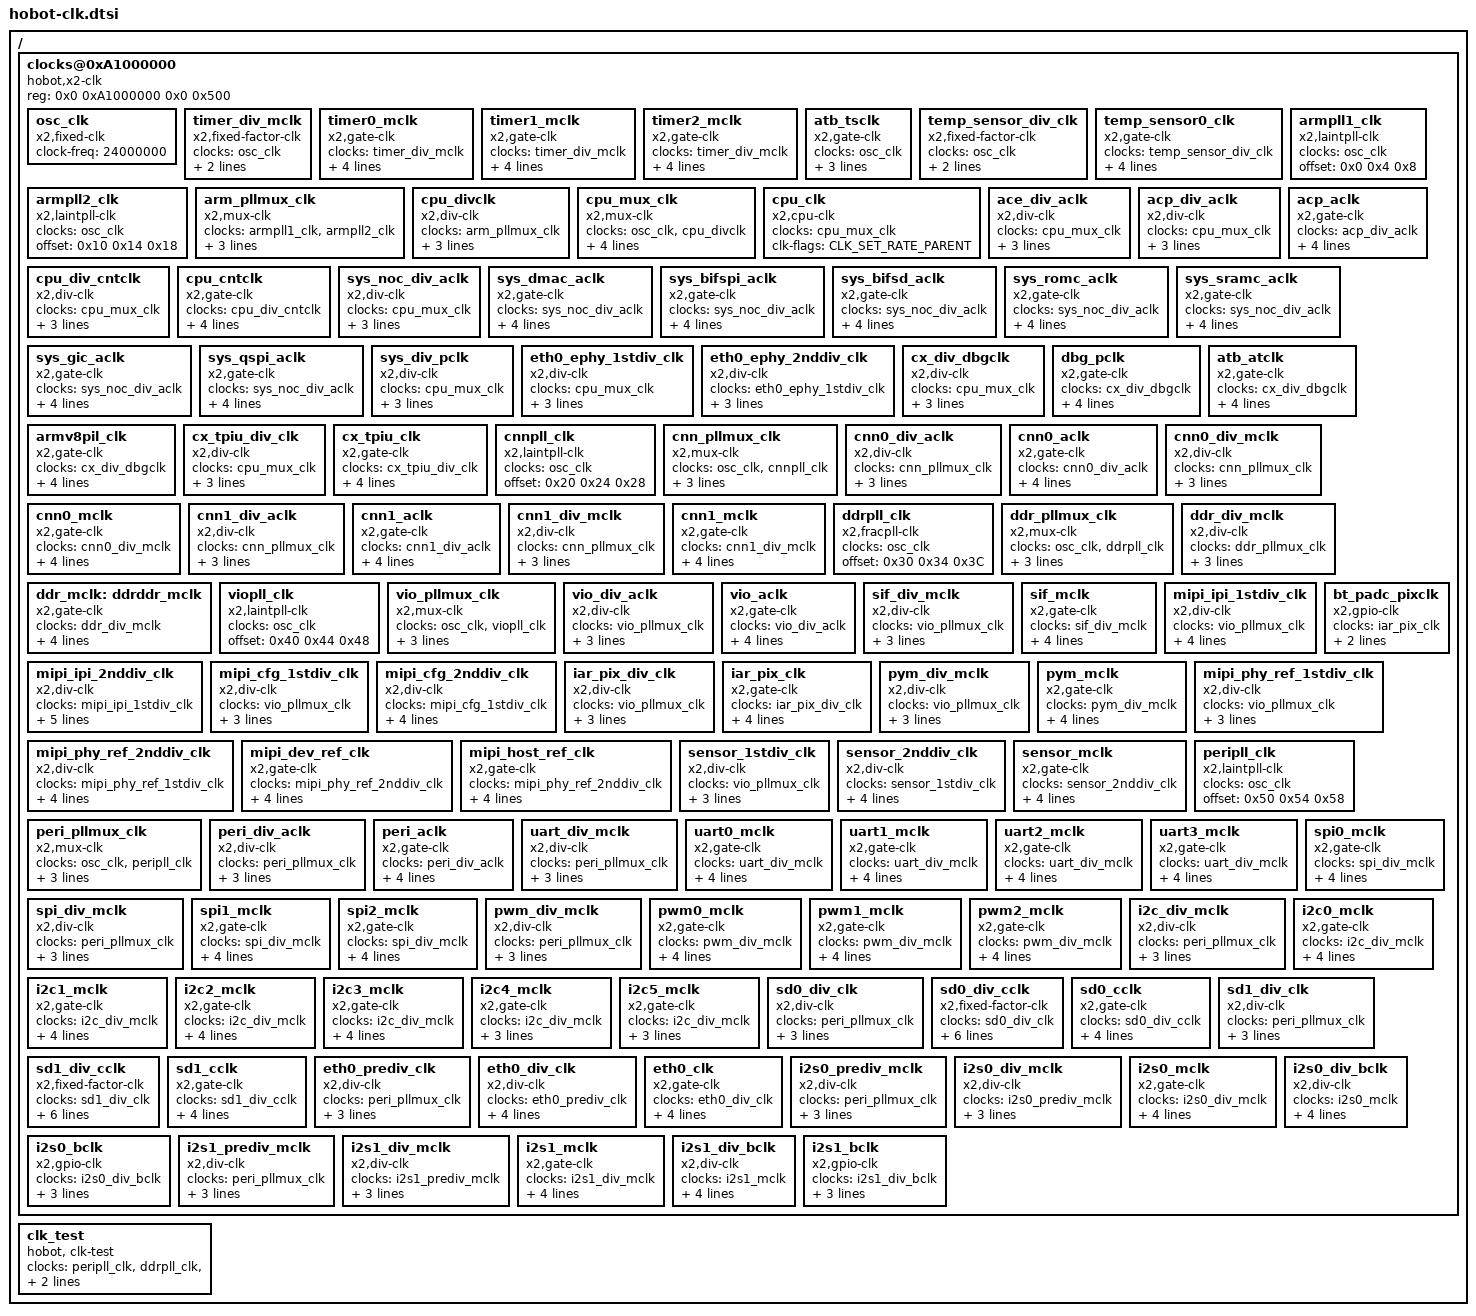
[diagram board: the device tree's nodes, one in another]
#include <dt-bindings/clk/hobot-clk.h>

/{
	clocks@0xA1000000 {
		compatible = "hobot,x2-clk";
		reg = <0x0 0xA1000000 0x0 0x500>;

		osc_clk: osc_clk {
			#clock-cells = <0>;
			compatible = "x2,fixed-clk";
			clock-freq = <24000000>;
		};

		timer_div_mclk: timer_div_mclk {
			#clock-cells = <0>;
			compatible = "x2,fixed-factor-clk";
			clocks = <&osc_clk>;
			clk-div = <24>;
			clk-mult = <1>;
		};

		timer0_mclk: timer0_mclk {
			#clock-cells = <0>;
			compatible = "x2,gate-clk";
			clocks = <&timer_div_mclk>;
			offset = <0x100 0x104 0x108 0x0>;
			bits = <8 8 8 32>;
			field = <1 1 1>;
			clk-flags = <CLK_SET_RATE_PARENT>;
		};

		timer1_mclk: timer1_mclk {
			#clock-cells = <0>;
			compatible = "x2,gate-clk";
			clocks = <&timer_div_mclk>;
			offset = <0x100 0x104 0x108 0x0>;
			bits = <9 9 9 32>;
			field = <1 1 1>;
			clk-flags = <CLK_SET_RATE_PARENT>;
		};

		timer2_mclk: timer2_mclk {
			#clock-cells = <0>;
			compatible = "x2,gate-clk";
			clocks = <&timer_div_mclk>;
			offset = <0x100 0x104 0x108 0x0>;
			bits = <10 10 10 32>;
			field = <1 1 1>;
			clk-flags = <CLK_SET_RATE_PARENT>;
		};

		atb_tsclk: atb_tsclk {
			#clock-cells = <0>;
			compatible = "x2,gate-clk";
			clocks = <&osc_clk>;
			offset = <0x110 0x114 0x118 0x0>;
			bits = <2 2 2 32>;
			field = <0x1 0x1 0x1>;
		};

		temp_sensor_div_clk: temp_sensor_div_clk {
			#clock-cells = <0>;
			compatible = "x2,fixed-factor-clk";
			clocks = <&osc_clk>;
			clk-div = <12>;
			clk-mult = <1>;
		};

		temp_sensor0_clk: temp_sensor0_clk {
			#clock-cells = <0>;
			compatible = "x2,gate-clk";
			clocks = <&temp_sensor_div_clk>;
			offset = <0x100 0x104 0x108 0x0>;
			bits = <12 12 12 32>;
			field = <1 1 1>;
			clk-flags = <CLK_SET_RATE_PARENT>;
		};

		armpll1_clk: armpll1_clk {
			#clock-cells = <0>;
			compatible = "x2,laintpll-clk";
			clocks = <&osc_clk>;
			offset = <0x0 0x4 0x8>;
		};

		armpll2_clk: armpll2_clk {
			#clock-cells = <0>;
			compatible = "x2,laintpll-clk";
			clocks = <&osc_clk>;
			offset = <0x10 0x14 0x18>;
		};

		arm_pllmux_clk: arm_pllmux_clk {
			#clock-cells = <0>;
			compatible = "x2,mux-clk";
			clocks = <&armpll1_clk>, <&armpll2_clk>;
			offset = <0x300>;
			bits = <0>;
			field = <0x1>;
		};

		cpu_divclk: cpu_divclk {
			#clock-cells = <0>;
			compatible = "x2,div-clk";
			clocks = <&arm_pllmux_clk>;
			offset = <0x204>;
			bits = <0>;
			field = <3>;
		};

		cpu_mux_clk: cpu_mux_clk {
			#clock-cells = <0>;
			compatible = "x2,mux-clk";
			clocks = <&osc_clk>, <&cpu_divclk>;
			offset = <0x300>;
			bits = <4>;
			field = <0x1>;
			clk-flags = <CLK_SET_RATE_PARENT>;
		};


		cpu_clk: cpu_clk {
			#clock-cells = <0>;
			compatible = "x2,cpu-clk";
			clocks = <&cpu_mux_clk>;
			clk-flags = <CLK_SET_RATE_PARENT>;
		};

		ace_div_aclk: ace_div_aclk {
			#clock-cells = <0>;
			compatible = "x2,div-clk";
			clocks = <&cpu_mux_clk>;
			offset = <0x204>;
			bits = <4>;
			field = <3>;
		};

		acp_div_aclk: acp_div_aclk {
			#clock-cells = <0>;
			compatible = "x2,div-clk";
			clocks = <&cpu_mux_clk>;
			offset = <0x200>;
			bits = <0>;
			field = <3>;
		};

		acp_aclk: acp_aclk {
			#clock-cells = <0>;
			compatible = "x2,gate-clk";
			clocks = <&acp_div_aclk>;
			offset = <0x100 0x104 0x108 0x208>;
			bits = <0 0 0 0>;
			field = <1 1 1 1>;
			clk-flags = <CLK_SET_RATE_PARENT>;
		};

		cpu_div_cntclk: cpu_div_cntclk {
			#clock-cells = <0>;
			compatible = "x2,div-clk";
			clocks = <&cpu_mux_clk>;
			offset = <0x200>;
			bits = <4>;
			field = <3>;
		};

		cpu_cntclk: cpu_cntclk {
			#clock-cells = <0>;
			compatible = "x2,gate-clk";
			clocks = <&cpu_div_cntclk>;
			offset = <0x100 0x104 0x108 0x208>;
			bits = <11 11 11 1>;
			field = <1 1 1 1>;
			clk-flags = <CLK_SET_RATE_PARENT>;
		};

		sys_noc_div_aclk: sys_noc_div_aclk {
			#clock-cells = <0>;
			compatible = "x2,div-clk";
			clocks = <&cpu_mux_clk>;
			offset = <0x204>;
			bits = <8>;
			field = <3>;
		};

		sys_dmac_aclk: sys_dmac_aclk {
			#clock-cells = <0>;
			compatible = "x2,gate-clk";
			clocks = <&sys_noc_div_aclk>;
			offset = <0x100 0x104 0x108 0x0>;
			bits = <7 7 7 32>;
			field = <1 1 1>;
			clk-flags = <CLK_SET_RATE_PARENT>;
		};

		sys_bifspi_aclk: sys_bifspi_aclk {
			#clock-cells = <0>;
			compatible = "x2,gate-clk";
			clocks = <&sys_noc_div_aclk>;
			offset = <0x100 0x104 0x108 0x0>;
			bits = <4 4 4 32>;
			field = <1 1 1>;
			clk-flags = <CLK_SET_RATE_PARENT>;
		};

		sys_bifsd_aclk: sys_bifsd_aclk {
			#clock-cells = <0>;
			compatible = "x2,gate-clk";
			clocks = <&sys_noc_div_aclk>;
			offset = <0x100 0x104 0x108 0x0>;
			bits = <5 5 5 32>;
			field = <1 1 1>;
			clk-flags = <CLK_SET_RATE_PARENT>;
		};

		sys_romc_aclk: sys_romc_aclk {
			#clock-cells = <0>;
			compatible = "x2,gate-clk";
			clocks = <&sys_noc_div_aclk>;
			offset = <0x100 0x104 0x108 0x0>;
			bits = <1 1 1 32>;
			field = <1 1 1>;
			clk-flags = <CLK_SET_RATE_PARENT>;
		};

		sys_sramc_aclk: sys_sramc_aclk {
			#clock-cells = <0>;
			compatible = "x2,gate-clk";
			clocks = <&sys_noc_div_aclk>;
			offset = <0x100 0x104 0x108 0x0>;
			bits = <2 2 2 32>;
			field = <1 1 1>;
			clk-flags = <CLK_SET_RATE_PARENT>;
		};

		sys_gic_aclk: sys_gic_aclk {
			#clock-cells = <0>;
			compatible = "x2,gate-clk";
			clocks = <&sys_noc_div_aclk>;
			offset = <0x100 0x104 0x108 0x0>;
			bits = <3 3 3 32>;
			field = <1 1 1>;
			clk-flags = <CLK_SET_RATE_PARENT>;
		};

		sys_qspi_aclk: sys_qspi_aclk {
			#clock-cells = <0>;
			compatible = "x2,gate-clk";
			clocks = <&sys_noc_div_aclk>;
			offset = <0x100 0x104 0x108 0x0>;
			bits = <6 6 6 32>;
			field = <1 1 1>;
			clk-flags = <CLK_SET_RATE_PARENT>;
		};

		sys_div_pclk: sys_div_pclk {
			#clock-cells = <0>;
			compatible = "x2,div-clk";
			clocks = <&cpu_mux_clk>;
			offset = <0x204>;
			bits = <12>;
			field = <3>;
		};

		eth0_ephy_1stdiv_clk: eth0_ephy_1stdiv_clk {
			#clock-cells = <0>;
			compatible = "x2,div-clk";
			clocks = <&cpu_mux_clk>;
			offset = <0x340>;
			bits = <12>;
			field = <5>;
		};

		eth0_ephy_2nddiv_clk: eth0_ephy_2nddiv_clk {
			#clock-cells = <0>;
			compatible = "x2,div-clk";
			clocks = <&eth0_ephy_1stdiv_clk>;
			offset = <0x340>;
			bits = <20>;
			field = <3>;
		};

		cx_div_dbgclk: cx_div_dbgclk {
			#clock-cells = <0>;
			compatible = "x2,div-clk";
			clocks = <&cpu_mux_clk>;
			offset = <0x210>;
			bits = <0>;
			field = <3>;
		};

		dbg_pclk: dbg_pclk {
			#clock-cells = <0>;
			compatible = "x2,gate-clk";
			clocks = <&cx_div_dbgclk>;
			offset = <0x110 0x114 0x118 0x0>;
			bits = <0 0 0 32>;
			field = <1 1 1>;
			clk-flags = <CLK_SET_RATE_PARENT>;
		};

		atb_atclk: atb_atclk {
			#clock-cells = <0>;
			compatible = "x2,gate-clk";
			clocks = <&cx_div_dbgclk>;
			offset = <0x110 0x114 0x118 0x0>;
			bits = <1 1 1 32>;
			field = <1 1 1>;
			clk-flags = <CLK_SET_RATE_PARENT>;
		};

		armv8pil_clk: armv8pil_clk {
			#clock-cells = <0>;
			compatible = "x2,gate-clk";
			clocks = <&cx_div_dbgclk>;
			offset = <0x110 0x114 0x118 0x0>;
			bits = <3 3 3 32>;
			field = <1 1 1>;
			clk-flags = <CLK_SET_RATE_PARENT>;
		};

		cx_tpiu_div_clk: cx_tpiu_div_clk {
			#clock-cells = <0>;
			compatible = "x2,div-clk";
			clocks = <&cpu_mux_clk>;
			offset = <0x210>;
			bits = <4>;
			field = <3>;
		};

		cx_tpiu_clk: cx_tpiu_clk {
			#clock-cells = <0>;
			compatible = "x2,gate-clk";
			clocks = <&cx_tpiu_div_clk>;
			offset = <0x110 0x114 0x118 0x218>;
			bits = <4 4 4 0>;
			field = <1 1 1 1>;
			clk-flags = <CLK_SET_RATE_PARENT>;
		};

		cnnpll_clk: cnnpll_clk {
			#clock-cells = <0>;
			compatible = "x2,laintpll-clk";
			clocks = <&osc_clk>;
			offset = <0x20 0x24 0x28>;
		};

		cnn_pllmux_clk: cnn_pllmux_clk {
			#clock-cells = <0>;
			compatible = "x2,mux-clk";
			clocks = <&osc_clk>, <&cnnpll_clk>;
			offset = <0x300>;
			bits = <8>;
			field = <0x1>;
		};

		cnn0_div_aclk: cnn0_div_aclk {
			#clock-cells = <0>;
			compatible = "x2,div-clk";
			clocks = <&cnn_pllmux_clk>;
			offset = <0x220>;
			bits = <0>;
			field = <3>;
		};

		cnn0_aclk: cnn0_aclk {
			#clock-cells = <0>;
			compatible = "x2,gate-clk";
			clocks = <&cnn0_div_aclk>;
			offset = <0x120 0x124 0x128 0x228>;
			bits = <0 0 0 0>;
			field = <1 1 1 1>;
			clk-flags = <CLK_SET_RATE_PARENT>;
		};

		cnn0_div_mclk: cnn0_div_mclk {
			#clock-cells = <0>;
			compatible = "x2,div-clk";
			clocks = <&cnn_pllmux_clk>;
			offset = <0x220>;
			bits = <4>;
			field = <3>;
		};

		cnn0_mclk: cnn0_mclk {
			#clock-cells = <0>;
			compatible = "x2,gate-clk";
			clocks = <&cnn0_div_mclk>;
			offset = <0x120 0x124 0x128 0x228>;
			bits = <1 1 1 1>;
			field = <1 1 1 1>;
			clk-flags = <CLK_SET_RATE_PARENT>;
		};


		cnn1_div_aclk: cnn1_div_aclk {
			#clock-cells = <0>;
			compatible = "x2,div-clk";
			clocks = <&cnn_pllmux_clk>;
			offset = <0x220>;
			bits = <8>;
			field = <3>;
		};

		cnn1_aclk: cnn1_aclk {
			#clock-cells = <0>;
			compatible = "x2,gate-clk";
			clocks = <&cnn1_div_aclk>;
			offset = <0x120 0x124 0x128 0x228>;
			bits = <4 4 4 2>;
			field = <1 1 1 1>;
			clk-flags = <CLK_SET_RATE_PARENT>;
		};

		cnn1_div_mclk: cnn1_div_mclk {
			#clock-cells = <0>;
			compatible = "x2,div-clk";
			clocks = <&cnn_pllmux_clk>;
			offset = <0x220>;
			bits = <12>;
			field = <3>;
		};

		cnn1_mclk: cnn1_mclk {
			#clock-cells = <0>;
			compatible = "x2,gate-clk";
			clocks = <&cnn1_div_mclk>;
			offset = <0x120 0x124 0x128 0x228>;
			bits = <5 5 5 3>;
			field = <1 1 1 1>;
			clk-flags = <CLK_SET_RATE_PARENT>;
		};

		ddrpll_clk: ddrpll_clk {
			#clock-cells = <0>;
			compatible = "x2,fracpll-clk";
			clocks = <&osc_clk>;
			offset = <0x30 0x34 0x3C>;
		};

		ddr_pllmux_clk: ddr_pllmux_clk {
			#clock-cells = <0>;
			compatible = "x2,mux-clk";
			clocks = <&osc_clk>, <&ddrpll_clk>;
			offset = <0x300>;
			bits = <12>;
			field = <0x1>;
		};

		ddr_div_mclk: ddr_div_mclk {
			#clock-cells = <0>;
			compatible = "x2,div-clk";
			clocks = <&ddr_pllmux_clk>;
			offset = <0x230>;
			bits = <0>;
			field = <3>;
		};

		ddr_mclk: ddrddr_mclk {
			#clock-cells = <0>;
			compatible = "x2,gate-clk";
			clocks = <&ddr_div_mclk>;
			offset = <0x130 0x134 0x138 0x238>;
			bits = <0 0 0 0>;
			field = <1 1 1 1>;
			clk-flags = <CLK_SET_RATE_PARENT>;
		};

		viopll_clk: viopll_clk {
			#clock-cells = <0>;
			compatible = "x2,laintpll-clk";
			clocks = <&osc_clk>;
			offset = <0x40 0x44 0x48>;
		};

		vio_pllmux_clk: vio_pllmux_clk {
			#clock-cells = <0>;
			compatible = "x2,mux-clk";
			clocks = <&osc_clk>, <&viopll_clk>;
			offset = <0x300>;
			bits = <16>;
			field = <0x1>;
		};

		vio_div_aclk: vio_div_aclk {
			#clock-cells = <0>;
			compatible = "x2,div-clk";
			clocks = <&vio_pllmux_clk>;
			offset = <0x240>;
			bits = <0>;
			field = <3>;
		};

		vio_aclk: vio_aclk {
			#clock-cells = <0>;
			compatible = "x2,gate-clk";
			clocks = <&vio_div_aclk>;
			offset = <0x140 0x144 0x148 0x248>;
			bits = <0 0 0 0>;
			field = <1 1 1 1>;
			clk-flags = <CLK_SET_RATE_PARENT>;
		};

		sif_div_mclk: sif_div_mclk {
			#clock-cells = <0>;
			compatible = "x2,div-clk";
			clocks = <&vio_pllmux_clk>;
			offset = <0x240>;
			bits = <12>;
			field = <3>;
		};

		sif_mclk: sif_mclk {
			#clock-cells = <0>;
			compatible = "x2,gate-clk";
			clocks = <&sif_div_mclk>;
			offset = <0x140 0x144 0x148 0x248>;
			bits = <1 1 1 1>;
			field = <1 1 1 1>;
			clk-flags = <CLK_SET_RATE_PARENT>;
		};

		mipi_ipi_1stdiv_clk: mipi_ipi_1stdiv_clk {
			#clock-cells = <0>;
			compatible = "x2,div-clk";
			clocks = <&vio_pllmux_clk>;
			offset = <0x240>;
			bits = <4>;
			field = <5>;
			clk-divider-flags = <CLK_DIVIDER_ROUND_DOWN>;
		};

		mipi_ipi_2nddiv_clk: mipi_ipi_2nddiv_clk {
			#clock-cells = <0>;
			compatible = "x2,div-clk";
			clocks = <&mipi_ipi_1stdiv_clk>;
			offset = <0x240>;
			bits = <9>;
			field = <3>;
			clk-divider-flags = <CLK_DIVIDER_ROUND_DOWN>;
			clk-flags = <CLK_SET_RATE_PARENT>;
		};

		mipi_cfg_1stdiv_clk: mipi_cfg_1stdiv_clk {
			#clock-cells = <0>;
			compatible = "x2,div-clk";
			clocks = <&vio_pllmux_clk>;
			offset = <0x240>;
			bits = <24>;
			field = <5>;
		};

		mipi_cfg_2nddiv_clk: mipi_cfg_2nddiv_clk {
			#clock-cells = <0>;
			compatible = "x2,div-clk";
			clocks = <&mipi_cfg_1stdiv_clk>;
			offset = <0x240>;
			bits = <29>;
			field = <3>;
			clk-flags = <CLK_SET_RATE_PARENT>;
		};

		iar_pix_div_clk: iar_pix_div_clk {
			#clock-cells = <0>;
			compatible = "x2,div-clk";
			clocks = <&vio_pllmux_clk>;
			offset = <0x240>;
			bits = <20>;
			field = <4>;
		};

		iar_pix_clk: iar_pix_clk {
			#clock-cells = <0>;
			compatible = "x2,gate-clk";
			clocks = <&iar_pix_div_clk>;
			offset = <0x140 0x144 0x148 0x248>;
			bits = <2 2 2 2>;
			field = <1 1 1 1>;
			clk-flags = <CLK_SET_RATE_PARENT>;
		};

		bt_padc_pixclk: bt_padc_pixclk {
			#clock-cells = <0>;
			compatible = "x2,gpio-clk";
			clocks = <&iar_pix_clk>;
			offset = <0x310>;
			bits = <16>;
		};

		pym_div_mclk: pym_div_mclk {
			#clock-cells = <0>;
			compatible = "x2,div-clk";
			clocks = <&vio_pllmux_clk>;
			offset = <0x240>;
			bits = <16>;
			field = <3>;
		};

		pym_mclk: pym_mclk {
			#clock-cells = <0>;
			compatible = "x2,gate-clk";
			clocks = <&pym_div_mclk>;
			offset = <0x140 0x144 0x148 0x248>;
			bits = <5 5 5 5>;
			field = <1 1 1 1>;
			clk-flags = <CLK_SET_RATE_PARENT>;
		};

		mipi_phy_ref_1stdiv_clk: mipi_phy_ref_1stdiv_clk {
			#clock-cells = <0>;
			compatible = "x2,div-clk";
			clocks = <&vio_pllmux_clk>;
			offset = <0x244>;
			bits = <0>;
			field = <5>;
		};

		mipi_phy_ref_2nddiv_clk: mipi_phy_ref_2nddiv_clk {
			#clock-cells = <0>;
			compatible = "x2,div-clk";
			clocks = <&mipi_phy_ref_1stdiv_clk>;
			offset = <0x244>;
			bits = <8>;
			field = <3>;
			clk-flags = <CLK_SET_RATE_PARENT>;
		};

		mipi_dev_ref_clk: mipi_dev_ref_clk {
			#clock-cells = <0>;
			compatible = "x2,gate-clk";
			clocks = <&mipi_phy_ref_2nddiv_clk>;
			offset = <0x140 0x144 0x148 0x0>;
			bits = <3 3 3 32>;
			field = <1 1 1>;
			clk-flags = <CLK_SET_RATE_PARENT>;
		};

		mipi_host_ref_clk: mipi_host_ref_clk {
			#clock-cells = <0>;
			compatible = "x2,gate-clk";
			clocks = <&mipi_phy_ref_2nddiv_clk>;
			offset = <0x140 0x144 0x148 0x0>;
			bits = <6 6 6 32>;
			field = <1 1 1>;
			clk-flags = <CLK_SET_RATE_PARENT>;
		};

		sensor_1stdiv_clk: sensor_1stdiv_clk {
			#clock-cells = <0>;
			compatible = "x2,div-clk";
			clocks = <&vio_pllmux_clk>;
			offset = <0x244>;
			bits = <12>;
			field = <5>;
		};

		sensor_2nddiv_clk: sensor_2nddiv_clk {
			#clock-cells = <0>;
			compatible = "x2,div-clk";
			clocks = <&sensor_1stdiv_clk>;
			offset = <0x244>;
			bits = <20>;
			field = <3>;
			clk-flags = <CLK_SET_RATE_PARENT>;
		};

		sensor_mclk: sensor_mclk {
			#clock-cells = <0>;
			compatible = "x2,gate-clk";
			clocks = <&sensor_2nddiv_clk>;
			offset = <0x140 0x144 0x148 0x248>;
			bits = <4 4 4 4>;
			field = <1 1 1 1>;
			clk-flags = <CLK_SET_RATE_PARENT>;
		};

		peripll_clk: peripll_clk {
			#clock-cells = <0>;
			compatible = "x2,laintpll-clk";
			clocks = <&osc_clk>;
			offset = <0x50 0x54 0x58>;
		};

		peri_pllmux_clk: peri_pllmux_clk {
			#clock-cells = <0>;
			compatible = "x2,mux-clk";
			clocks = <&osc_clk>, <&peripll_clk>;
			offset = <0x300>;
			bits = <20>;
			field = <0x1>;
		};

		peri_div_aclk: peri_div_aclk {
			#clock-cells = <0>;
			compatible = "x2,div-clk";
			clocks = <&peri_pllmux_clk>;
			offset = <0x250>;
			bits = <0>;
			field = <3>;
		};

		peri_aclk: peri_aclk {
			#clock-cells = <0>;
			compatible = "x2,gate-clk";
			clocks = <&peri_div_aclk>;
			offset = <0x150 0x154 0x158 0x258>;
			bits = <0 0 0 0>;
			field = <1 1 1 1>;
			clk-flags = <CLK_SET_RATE_PARENT>;
		};

		uart_div_mclk: uart_div_mclk {
			#clock-cells = <0>;
			compatible = "x2,div-clk";
			clocks = <&peri_pllmux_clk>;
			offset = <0x250>;
			bits = <4>;
			field = <4>;
		};

		uart0_mclk: uart0_mclk {
			#clock-cells = <0>;
			compatible = "x2,gate-clk";
			clocks = <&uart_div_mclk>;
			offset = <0x150 0x154 0x158 0x0>;
			bits = <1 1 1 32>;
			field = <0x1 0x1 0x1>;
			clk-flags = <CLK_SET_RATE_PARENT>;
		};

		uart1_mclk: uart1_mclk {
			#clock-cells = <0>;
			compatible = "x2,gate-clk";
			clocks = <&uart_div_mclk>;
			offset = <0x150 0x154 0x158 0x0>;
			bits = <2 2 2 32>;
			field = <1 1 1>;
			clk-flags = <CLK_SET_RATE_PARENT>;
		};

		uart2_mclk: uart2_mclk {
			#clock-cells = <0>;
			compatible = "x2,gate-clk";
			clocks = <&uart_div_mclk>;
			offset = <0x150 0x154 0x158 0x0>;
			bits = <3 3 3 32>;
			field = <1 1 1>;
			clk-flags = <CLK_SET_RATE_PARENT>;
		};

		uart3_mclk: uart3_mclk {
			#clock-cells = <0>;
			compatible = "x2,gate-clk";
			clocks = <&uart_div_mclk>;
			offset = <0x150 0x154 0x158 0x0>;
			bits = <4 4 4 32>;
			field = <1 1 1>;
			clk-flags = <CLK_SET_RATE_PARENT>;
		};

		spi_div_mclk: spi_div_mclk {
			#clock-cells = <0>;
			compatible = "x2,div-clk";
			clocks = <&peri_pllmux_clk>;
			offset = <0x250>;
			bits = <8>;
			field = <4>;
		};

		spi0_mclk: spi0_mclk {
			#clock-cells = <0>;
			compatible = "x2,gate-clk";
			clocks = <&spi_div_mclk>;
			offset = <0x150 0x154 0x158 0x0>;
			bits = <5 5 5 32>;
			field = <1 1 1>;
			clk-flags = <CLK_SET_RATE_PARENT>;
		};

		spi1_mclk: spi1_mclk {
			#clock-cells = <0>;
			compatible = "x2,gate-clk";
			clocks = <&spi_div_mclk>;
			offset = <0x150 0x154 0x158 0x0>;
			bits = <6 6 6 32>;
			field = <1 1 1>;
			clk-flags = <CLK_SET_RATE_PARENT>;
		};

		spi2_mclk: spi2_mclk {
			#clock-cells = <0>;
			compatible = "x2,gate-clk";
			clocks = <&spi_div_mclk>;
			offset = <0x150 0x154 0x158 0x0>;
			bits = <7 7 7 32>;
			field = <1 1 1>;
			clk-flags = <CLK_SET_RATE_PARENT>;
		};

		pwm_div_mclk: pwm_div_mclk {
			#clock-cells = <0>;
			compatible = "x2,div-clk";
			clocks = <&peri_pllmux_clk>;
			offset = <0x250>;
			bits = <12>;
			field = <4>;
		};

		pwm0_mclk: pwm0_mclk {
			#clock-cells = <0>;
			compatible = "x2,gate-clk";
			clocks = <&pwm_div_mclk>;
			offset = <0x150 0x154 0x158 0x0>;
			bits = <8 8 8 32>;
			field = <1 1 1>;
			clk-flags = <CLK_SET_RATE_PARENT>;
		};

		pwm1_mclk: pwm1_mclk {
			#clock-cells = <0>;
			compatible = "x2,gate-clk";
			clocks = <&pwm_div_mclk>;
			offset = <0x150 0x154 0x158 0x0>;
			bits = <9 9 9 32>;
			field = <1 1 1>;
			clk-flags = <CLK_SET_RATE_PARENT>;
		};

		pwm2_mclk: pwm2_mclk {
			#clock-cells = <0>;
			compatible = "x2,gate-clk";
			clocks = <&pwm_div_mclk>;
			offset = <0x150 0x154 0x158 0x0>;
			bits = <10 10 10 32>;
			field = <1 1 1>;
			clk-flags = <CLK_SET_RATE_PARENT>;
		};

		i2c_div_mclk: i2c_div_mclk {
			#clock-cells = <0>;
			compatible = "x2,div-clk";
			clocks = <&peri_pllmux_clk>;
			offset = <0x250>;
			bits = <16>;
			field = <4>;
		};

		i2c0_mclk: i2c0_mclk {
			#clock-cells = <0>;
			compatible = "x2,gate-clk";
			clocks = <&i2c_div_mclk>;
			offset = <0x150 0x154 0x158 0x0>;
			bits = <11 11 11 32>;
			field = <1 1 1>;
			clk-flags = <CLK_SET_RATE_PARENT>;
		};

		i2c1_mclk: i2c1_mclk {
			#clock-cells = <0>;
			compatible = "x2,gate-clk";
			clocks = <&i2c_div_mclk>;
			offset = <0x150 0x154 0x158 0x0>;
			bits = <12 12 12 32>;
			field = <1 1 1>;
			clk-flags = <CLK_SET_RATE_PARENT>;
		};

		i2c2_mclk: i2c2_mclk {
			#clock-cells = <0>;
			compatible = "x2,gate-clk";
			clocks = <&i2c_div_mclk>;
			offset = <0x150 0x154 0x158 0x0>;
			bits = <13 13 13 32>;
			field = <1 1 1>;
			clk-flags = <CLK_SET_RATE_PARENT>;
		};

		i2c3_mclk: i2c3_mclk {
			#clock-cells = <0>;
			compatible = "x2,gate-clk";
			clocks = <&i2c_div_mclk>;
			offset = <0x150 0x154 0x158 0x0>;
			bits = <14 14 14 32>;
			field = <1 1 1>;
			clk-flags = <CLK_SET_RATE_PARENT>;
		};

                i2c4_mclk: i2c4_mclk {
                        #clock-cells = <0>;
                        compatible = "x2,gate-clk";
                        clocks = <&i2c_div_mclk>;
                        offset = <0x150 0x154 0x158>;
                        bits = <15 15 15>;
                        field = <0x1 0x1 0x1>;
                };

                i2c5_mclk: i2c5_mclk {
                        #clock-cells = <0>;
                        compatible = "x2,gate-clk";
                        clocks = <&i2c_div_mclk>;
                        offset = <0x150 0x154 0x158>;
                        bits = <16 16 16>;
                        field = <0x1 0x1 0x1>;
                };

		sd0_div_clk: sd0_div_clk {
			#clock-cells = <0>;
			compatible = "x2,div-clk";
			clocks = <&peri_pllmux_clk>;
			offset = <0x320>;
			bits = <0>;
			field = <4>;
		};

		sd0_div_cclk: sd0_div_cclk {
			#clock-cells = <0>;
			compatible = "x2,fixed-factor-clk";
			clocks = <&sd0_div_clk>;
			offset = <0x320>;
			bits = <4>;
			field = <3>;
			clk-div = <8>;
			clk-mult = <1>;
			clk-flags = <CLK_SET_RATE_PARENT>;
		};

		sd0_cclk: sd0_cclk {
			#clock-cells = <0>;
			compatible = "x2,gate-clk";
			clocks = <&sd0_div_cclk>;
			offset = <0x150 0x154 0x158 0x258>;
			bits = <15 15 15 1>;
			field = <1 1 1 1>;
			clk-flags = <CLK_SET_RATE_PARENT>;
		};

		sd1_div_clk: sd1_div_clk {
			#clock-cells = <0>;
			compatible = "x2,div-clk";
			clocks = <&peri_pllmux_clk>;
			offset = <0x330>;
			bits = <0>;
			field = <4>;
		};

		sd1_div_cclk: sd1_div_cclk {
			#clock-cells = <0>;
			compatible = "x2,fixed-factor-clk";
			clocks = <&sd1_div_clk>;
			offset = <0x330>;
			bits = <4>;
			field = <3>;
			clk-div = <8>;
			clk-mult = <1>;
			clk-flags = <CLK_SET_RATE_PARENT>;
		};

		sd1_cclk: sd1_cclk {
			#clock-cells = <0>;
			compatible = "x2,gate-clk";
			clocks = <&sd1_div_cclk>;
			offset = <0x150 0x154 0x158 0x258>;
			bits = <16 16 16 2>;
			field = <1 1 1 1>;
			clk-flags = <CLK_SET_RATE_PARENT>;
		};

		eth0_prediv_clk: eth0_prediv_clk {
			#clock-cells = <0>;
			compatible = "x2,div-clk";
			clocks = <&peri_pllmux_clk>;
			offset = <0x340>;
			bits = <0>;
			field = <5>;
		};

		eth0_div_clk: eth0_div_clk {
			#clock-cells = <0>;
			compatible = "x2,div-clk";
			clocks = <&eth0_prediv_clk>;
			offset = <0x340>;
			bits = <8>;
			field = <3>;
			clk-flags = <CLK_SET_RATE_PARENT>;
		};

		eth0_clk: eth0_clk {
			#clock-cells = <0>;
			compatible = "x2,gate-clk";
			clocks = <&eth0_div_clk>;
			offset = <0x150 0x154 0x158 0x258>;
			bits = <17 17 17 3>;
			field = <1 1 1 1>;
			clk-flags = <CLK_SET_RATE_PARENT>;
		};

		i2s0_prediv_mclk: i2s0_prediv_mclk {
			#clock-cells = <0>;
			compatible = "x2,div-clk";
			clocks = <&peri_pllmux_clk>;
			offset = <0x350>;
			bits = <0>;
			field = <5>;
		};

		i2s0_div_mclk: i2s0_div_mclk {
			#clock-cells = <0>;
			compatible = "x2,div-clk";
			clocks = <&i2s0_prediv_mclk>;
			offset = <0x350>;
			bits = <8>;
			field = <5>;
		};

		i2s0_mclk: i2s0_mclk {
			#clock-cells = <0>;
			compatible = "x2,gate-clk";
			clocks = <&i2s0_div_mclk>;
			offset = <0x150 0x154 0x158 0x258>;
			bits = <18 18 18 5>;
			field = <1 1 1 1>;
			clk-flags = <CLK_SET_RATE_PARENT>;
		};

		i2s0_div_bclk: i2s0_div_bclk {
			#clock-cells = <0>;
			compatible = "x2,div-clk";
			clocks = <&i2s0_mclk>;
			offset = <0x350>;
			bits = <16>;
			field = <7>;
			clk-flags = <CLK_SET_RATE_PARENT>;
		};

		i2s0_bclk: i2s0_bclk {
			#clock-cells = <0>;
			compatible = "x2,gpio-clk";
			clocks = <&i2s0_div_bclk>;
			offset = <0x350>;
			bits = <20>;
			clk-flags = <CLK_SET_RATE_PARENT>;
		};

		i2s1_prediv_mclk: i2s1_prediv_mclk {
			#clock-cells = <0>;
			compatible = "x2,div-clk";
			clocks = <&peri_pllmux_clk>;
			offset = <0x360>;
			bits = <0>;
			field = <5>;
		};

		i2s1_div_mclk: i2s1_div_mclk {
			#clock-cells = <0>;
			compatible = "x2,div-clk";
			clocks = <&i2s1_prediv_mclk>;
			offset = <0x360>;
			bits = <8>;
			field = <5>;
		};

		i2s1_mclk: i2s1_mclk {
			#clock-cells = <0>;
			compatible = "x2,gate-clk";
			clocks = <&i2s1_div_mclk>;
			offset = <0x150 0x154 0x158 0x258>;
			bits = <19 19 19 6>;
			field = <1 1 1 1>;
			clk-flags = <CLK_SET_RATE_PARENT>;
		};

		i2s1_div_bclk: i2s1_div_bclk {
			#clock-cells = <0>;
			compatible = "x2,div-clk";
			clocks = <&i2s1_mclk>;
			offset = <0x360>;
			bits = <16>;
			field = <3>;
			clk-flags = <CLK_SET_RATE_PARENT>;
		};

		i2s1_bclk: i2s1_bclk {
			#clock-cells = <0>;
			compatible = "x2,gpio-clk";
			clocks = <&i2s1_div_bclk>;
			offset = <0x360>;
			bits = <20>;
			clk-flags = <CLK_SET_RATE_PARENT>;
		};
	};
	clk_test: clk_test {
		compatible = "hobot, clk-test";
		clock-names = "laintpll","fracpll","mux","divider","gate","osc";
		clocks = <&peripll_clk>,
				 <&ddrpll_clk>,
				 <&peri_pllmux_clk>,
				 <&i2c_div_mclk>,
				 <&i2c0_mclk>,
				 <&osc_clk>;
	};
};
